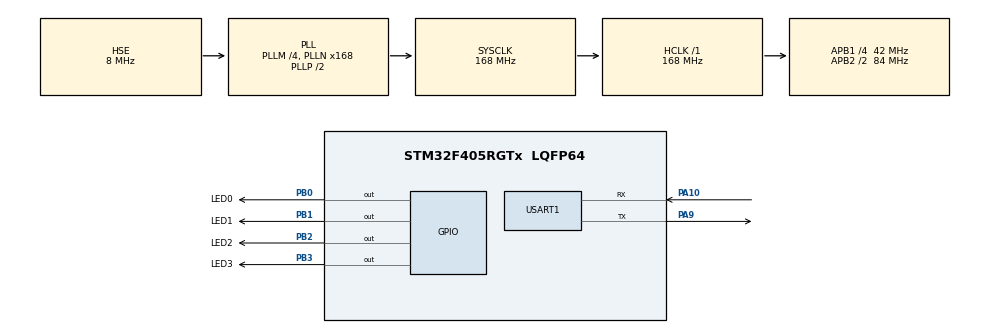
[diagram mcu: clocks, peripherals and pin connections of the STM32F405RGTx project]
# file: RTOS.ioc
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FREERTOS.Tasks01=defaultTask,24,128,StartDefaultTask,Default,NULL,Dynamic,NULL,NULL;myTask02,8,128,StartTask02,Default,NULL,Dynamic,NULL,NULL
Mcu.Family=STM32F4
Mcu.Name=STM32F405RGTx
Mcu.Package=LQFP64
NVIC.PriorityGroup=NVIC_PRIORITYGROUP_4
NVIC.USART1_IRQn=true\:5\:0\:false\:false\:true\:true\:true\:true\:true
PA10.Mode=Asynchronous
PA10.Signal=USART1_RX
PA9.Mode=Asynchronous
PA9.Signal=USART1_TX
PB0.GPIO_Label=LED0
PB0.Signal=GPIO_Output
PB1.GPIO_Label=LED1
PB1.Signal=GPIO_Output
PB2.GPIO_Label=LED2
PB2.Signal=GPIO_Output
PB3.GPIO_Label=LED3
PB3.Signal=GPIO_Output
PH0-OSC_IN.Mode=HSE-External-Oscillator
PH0-OSC_IN.Signal=RCC_OSC_IN
PH1-OSC_OUT.Mode=HSE-External-Oscillator
PH1-OSC_OUT.Signal=RCC_OSC_OUT
ProjectManager.HeapSize=0x200
ProjectManager.StackSize=0x400
ProjectManager.TargetToolchain=STM32CubeIDE
RCC.48MHZClocksFreq_Value=84000000
RCC.AHBFreq_Value=168000000
RCC.APB1CLKDivider=RCC_HCLK_DIV4
RCC.APB1Freq_Value=42000000
RCC.APB1TimFreq_Value=84000000
RCC.APB2CLKDivider=RCC_HCLK_DIV2
RCC.APB2Freq_Value=84000000
RCC.APB2TimFreq_Value=168000000
RCC.CortexFreq_Value=168000000
RCC.HCLKFreq_Value=168000000
RCC.HSE_VALUE=8000000
RCC.HSI_VALUE=16000000
RCC.LSE_VALUE=32768
RCC.PLLM=4
RCC.PLLN=168
RCC.PLLSourceVirtual=RCC_PLLSOURCE_HSE
RCC.SYSCLKFreq_VALUE=168000000
RCC.SYSCLKSource=RCC_SYSCLKSOURCE_PLLCLK
RCC.VCOOutputFreq_Value=336000000
USART1.VirtualMode=VM_ASYNC
VP_FREERTOS_VS_CMSIS_V2.Mode=CMSIS_V2
board=custom

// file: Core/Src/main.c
/* USER CODE BEGIN Header */
/**
  ******************************************************************************
  * @file           : main.c
  * @brief          : Main program body
  ******************************************************************************
  * @attention
  *
  * Copyright (c) 2022 STMicroelectronics.
  * All rights reserved.
  *
  * This software is licensed under terms that can be found in the LICENSE file
  * in the root directory of this software component.
  * If no LICENSE file comes with this software, it is provided AS-IS.
  *
  ******************************************************************************
  */
/* USER CODE END Header */
#include "main.h"
#include "cmsis_os.h"

UART_HandleTypeDef huart1;

/* Definitions for defaultTask */
osThreadId_t defaultTaskHandle;
const osThreadAttr_t defaultTask_attributes = {
  .name = "defaultTask",
  .stack_size = 128 * 4,
  .priority = (osPriority_t) osPriorityNormal,
};
/* Definitions for myTask02 */
osThreadId_t myTask02Handle;
const osThreadAttr_t myTask02_attributes = {
  .name = "myTask02",
  .stack_size = 128 * 4,
  .priority = (osPriority_t) osPriorityLow,
};

void SystemClock_Config(void);
static void MX_GPIO_Init(void);
static void MX_USART1_UART_Init(void);
void StartDefaultTask(void *argument);
void StartTask02(void *argument);

int main(void)
{

  /* MCU Configuration--------------------------------------------------------*/

  /* Reset of all peripherals, Initializes the Flash interface and the Systick. */
  HAL_Init();

  /* Configure the system clock */
  SystemClock_Config();

  /* Initialize all configured peripherals */
  MX_GPIO_Init();
  MX_USART1_UART_Init();

  /* Init scheduler */
  osKernelInitialize();

  /* Create the thread(s) */
  /* creation of defaultTask */
  defaultTaskHandle = osThreadNew(StartDefaultTask, NULL, &defaultTask_attributes);

  /* creation of myTask02 */
  myTask02Handle = osThreadNew(StartTask02, NULL, &myTask02_attributes);

  /* Start scheduler */
  osKernelStart();

  /* We should never get here as control is now taken by the scheduler */
  /* Infinite loop */
  while (1)
  {

  }
}

void SystemClock_Config(void)
{
  RCC_OscInitTypeDef RCC_OscInitStruct = {0};
  RCC_ClkInitTypeDef RCC_ClkInitStruct = {0};

  /** Configure the main internal regulator output voltage
  */
  __HAL_RCC_PWR_CLK_ENABLE();
  __HAL_PWR_VOLTAGESCALING_CONFIG(PWR_REGULATOR_VOLTAGE_SCALE1);

  /** Initializes the RCC Oscillators according to the specified parameters
  * in the RCC_OscInitTypeDef structure.
  */
  RCC_OscInitStruct.OscillatorType = RCC_OSCILLATORTYPE_HSE;
  RCC_OscInitStruct.HSEState = RCC_HSE_ON;
  RCC_OscInitStruct.PLL.PLLState = RCC_PLL_ON;
  RCC_OscInitStruct.PLL.PLLSource = RCC_PLLSOURCE_HSE;
  RCC_OscInitStruct.PLL.PLLM = 4;
  RCC_OscInitStruct.PLL.PLLN = 168;
  RCC_OscInitStruct.PLL.PLLP = RCC_PLLP_DIV2;
  RCC_OscInitStruct.PLL.PLLQ = 4;
  if (HAL_RCC_OscConfig(&RCC_OscInitStruct) != HAL_OK)
  {
    Error_Handler();
  }

  /** Initializes the CPU, AHB and APB buses clocks
  */
  RCC_ClkInitStruct.ClockType = RCC_CLOCKTYPE_HCLK|RCC_CLOCKTYPE_SYSCLK
                              |RCC_CLOCKTYPE_PCLK1|RCC_CLOCKTYPE_PCLK2;
  RCC_ClkInitStruct.SYSCLKSource = RCC_SYSCLKSOURCE_PLLCLK;
  RCC_ClkInitStruct.AHBCLKDivider = RCC_SYSCLK_DIV1;
  RCC_ClkInitStruct.APB1CLKDivider = RCC_HCLK_DIV4;
  RCC_ClkInitStruct.APB2CLKDivider = RCC_HCLK_DIV2;

  if (HAL_RCC_ClockConfig(&RCC_ClkInitStruct, FLASH_LATENCY_5) != HAL_OK)
  {
    Error_Handler();
  }
}

static void MX_USART1_UART_Init(void)
{

  huart1.Instance = USART1;
  huart1.Init.BaudRate = 115200;
  huart1.Init.WordLength = UART_WORDLENGTH_8B;
  huart1.Init.StopBits = UART_STOPBITS_1;
  huart1.Init.Parity = UART_PARITY_NONE;
  huart1.Init.Mode = UART_MODE_TX_RX;
  huart1.Init.HwFlowCtl = UART_HWCONTROL_NONE;
  huart1.Init.OverSampling = UART_OVERSAMPLING_16;
  if (HAL_UART_Init(&huart1) != HAL_OK)
  {
    Error_Handler();
  }

}

static void MX_GPIO_Init(void)
{
  GPIO_InitTypeDef GPIO_InitStruct = {0};

  /* GPIO Ports Clock Enable */
  __HAL_RCC_GPIOH_CLK_ENABLE();
  __HAL_RCC_GPIOB_CLK_ENABLE();
  __HAL_RCC_GPIOA_CLK_ENABLE();

  /*Configure GPIO pin Output Level */
  HAL_GPIO_WritePin(GPIOB, LED0_Pin|LED1_Pin|LED2_Pin|LED3_Pin, GPIO_PIN_RESET);

  /*Configure GPIO pins : LED0_Pin LED1_Pin LED2_Pin LED3_Pin */
  GPIO_InitStruct.Pin = LED0_Pin|LED1_Pin|LED2_Pin|LED3_Pin;
  GPIO_InitStruct.Mode = GPIO_MODE_OUTPUT_PP;
  GPIO_InitStruct.Pull = GPIO_NOPULL;
  GPIO_InitStruct.Speed = GPIO_SPEED_FREQ_LOW;
  HAL_GPIO_Init(GPIOB, &GPIO_InitStruct);

}

void StartDefaultTask(void *argument)
{
  /* USER CODE BEGIN 5 */
  /* Infinite loop */
  for(;;)
  {
    osDelay(100);
    HAL_GPIO_TogglePin(GPIOB, LED0_Pin);
  }
  /* USER CODE END 5 */
}

void StartTask02(void *argument)
{
  /* USER CODE BEGIN StartTask02 */
  /* Infinite loop */
  for(;;)
  {
    osDelay(200);
    HAL_GPIO_TogglePin(GPIOB, LED1_Pin);
  }
  /* USER CODE END StartTask02 */
}

void Error_Handler(void)
{
  __disable_irq();
  while (1)
  {
  }
}
